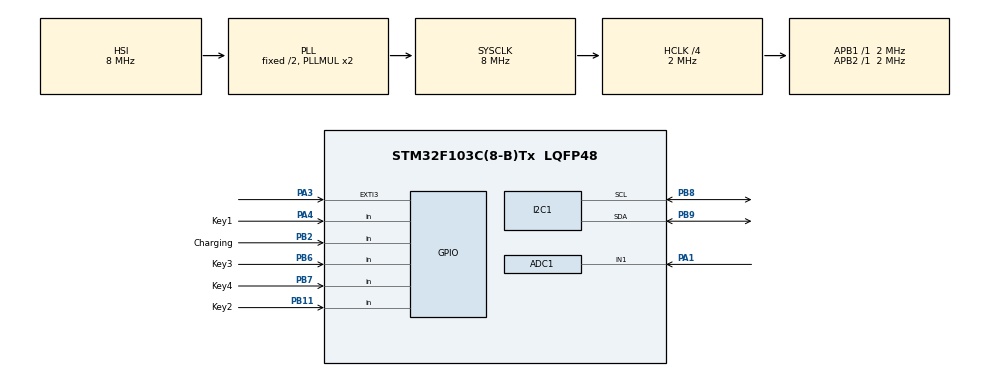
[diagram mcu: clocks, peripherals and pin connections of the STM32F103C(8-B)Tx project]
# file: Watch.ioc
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ADC1.Channel-1\#ChannelRegularConversion=ADC_CHANNEL_1
ADC1.ContinuousConvMode=ENABLE
ADC1.NbrOfConversionFlag=1
ADC1.Rank-1\#ChannelRegularConversion=1
ADC1.SamplingTime-1\#ChannelRegularConversion=ADC_SAMPLETIME_1CYCLE_5
ADC1.master=1
Mcu.Family=STM32F1
Mcu.Name=STM32F103C(8-B)Tx
Mcu.Package=LQFP48
NVIC.PriorityGroup=NVIC_PRIORITYGROUP_4
NVIC.TIM4_IRQn=true\:0\:0\:false\:false\:true\:true\:true\:true
PA1.Signal=ADCx_IN1
PA13.Mode=Serial_Wire
PA13.Signal=SYS_JTMS-SWDIO
PA14.Mode=Serial_Wire
PA14.Signal=SYS_JTCK-SWCLK
PA3.GPIO_ModeDefaultEXTI=GPIO_MODE_EVT_FALLING
PA3.GPIO_PuPd=GPIO_PULLUP
PA3.Signal=GPXTI3
PA4.GPIO_Label=Key1
PA4.GPIO_PuPd=GPIO_PULLUP
PA4.Signal=GPIO_Input
PB11.GPIO_Label=Key2
PB11.GPIO_PuPd=GPIO_PULLUP
PB11.Signal=GPIO_Input
PB2.GPIO_Label=Charging
PB2.GPIO_PuPd=GPIO_PULLDOWN
PB2.Signal=GPIO_Input
PB6.GPIO_Label=Key3
PB6.GPIO_PuPd=GPIO_PULLUP
PB6.Signal=GPIO_Input
PB7.GPIO_Label=Key4
PB7.GPIO_PuPd=GPIO_PULLUP
PB7.Signal=GPIO_Input
PB8.Mode=I2C
PB8.Signal=I2C1_SCL
PB9.Mode=I2C
PB9.Signal=I2C1_SDA
PC14-OSC32_IN.Mode=LSE-External-Oscillator
PC14-OSC32_IN.Signal=RCC_OSC32_IN
PC15-OSC32_OUT.Mode=LSE-External-Oscillator
PC15-OSC32_OUT.Signal=RCC_OSC32_OUT
ProjectManager.HeapSize=0x200
ProjectManager.StackSize=0x400
ProjectManager.TargetToolchain=CMake
RCC.AHBCLKDivider=RCC_SYSCLK_DIV4
RCC.AHBFreq_Value=2000000
RCC.APB1Freq_Value=2000000
RCC.APB1TimFreq_Value=2000000
RCC.APB2Freq_Value=2000000
RCC.APB2TimFreq_Value=2000000
RCC.HCLKFreq_Value=2000000
RCC.PLLSourceVirtual=RCC_PLLSOURCE_HSI_DIV2
RCC.RTCClockSelection=RCC_RTCCLKSOURCE_LSE
RCC.SYSCLKFreq_VALUE=8000000
RCC.SYSCLKSource=RCC_SYSCLKSOURCE_PLLCLK
RCC.USBFreq_Value=8000000
RTC.AsynchPrediv=RTC_AUTO_1_SECOND
RTC.AutoPrediv=RTC_AUTO_1_SECOND
RTC.Format=RTC_FORMAT_BIN
SH.ADCx_IN1.0=ADC1_IN1,IN1
TIM4.Period=10
TIM4.Prescaler=2000
VP_RTC_VS_RTC_Activate.Mode=RTC_Enabled
VP_TIM4_VS_ClockSourceINT.Mode=Internal
board=custom

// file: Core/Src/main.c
/* USER CODE BEGIN Header */
/**
 ******************************************************************************
 * @file           : main.c
 * @brief          : Main program body
 ******************************************************************************
 * @attention
 *
 * Copyright (c) 2025 STMicroelectronics.
 * All rights reserved.
 *
 * This software is licensed under terms that can be found in the LICENSE file
 * in the root directory of this software component.
 * If no LICENSE file comes with this software, it is provided AS-IS.
 *
 ******************************************************************************
 */
/* USER CODE END Header */
#include "main.h"
#include "adc.h"
#include "i2c.h"
#include "rtc.h"
#include "tim.h"
#include "gpio.h"

/* USER CODE BEGIN Includes */

#include "key.h"
#include "oled.h"
#include "watch.h"

/* USER CODE END Includes */

void SystemClock_Config(void);

int main(void)
{

  /* MCU Configuration--------------------------------------------------------*/

  /* Reset of all peripherals, Initializes the Flash interface and the Systick. */
  HAL_Init();

  /* Configure the system clock */
  SystemClock_Config();

  /* Initialize all configured peripherals */
  MX_GPIO_Init();
  MX_ADC1_Init();
  MX_RTC_Init();
  MX_TIM4_Init();
  MX_I2C1_Init();
  /* USER CODE BEGIN 2 */

    HAL_TIM_Base_Start_IT(&htim4);

    HAL_ADCEx_Calibration_Start(&hadc1);
    HAL_ADC_Start(&hadc1);

    oled_init();
    watch_init();

  /* USER CODE END 2 */

  /* Infinite loop */
  /* USER CODE BEGIN WHILE */
    while (1)
    {
        key_update();
        watch_update();
        oled_flush();
    /* USER CODE END WHILE */

    }
}

void SystemClock_Config(void)
{
  RCC_OscInitTypeDef RCC_OscInitStruct = {0};
  RCC_ClkInitTypeDef RCC_ClkInitStruct = {0};
  RCC_PeriphCLKInitTypeDef PeriphClkInit = {0};

  /** Initializes the RCC Oscillators according to the specified parameters
  * in the RCC_OscInitTypeDef structure.
  */
  RCC_OscInitStruct.OscillatorType = RCC_OSCILLATORTYPE_HSI|RCC_OSCILLATORTYPE_LSE;
  RCC_OscInitStruct.LSEState = RCC_LSE_ON;
  RCC_OscInitStruct.HSIState = RCC_HSI_ON;
  RCC_OscInitStruct.HSICalibrationValue = RCC_HSICALIBRATION_DEFAULT;
  RCC_OscInitStruct.PLL.PLLState = RCC_PLL_ON;
  RCC_OscInitStruct.PLL.PLLSource = RCC_PLLSOURCE_HSI_DIV2;
  RCC_OscInitStruct.PLL.PLLMUL = RCC_PLL_MUL2;
  if (HAL_RCC_OscConfig(&RCC_OscInitStruct) != HAL_OK)
  {
    Error_Handler();
  }

  /** Initializes the CPU, AHB and APB buses clocks
  */
  RCC_ClkInitStruct.ClockType = RCC_CLOCKTYPE_HCLK|RCC_CLOCKTYPE_SYSCLK
                              |RCC_CLOCKTYPE_PCLK1|RCC_CLOCKTYPE_PCLK2;
  RCC_ClkInitStruct.SYSCLKSource = RCC_SYSCLKSOURCE_PLLCLK;
  RCC_ClkInitStruct.AHBCLKDivider = RCC_SYSCLK_DIV4;
  RCC_ClkInitStruct.APB1CLKDivider = RCC_HCLK_DIV1;
  RCC_ClkInitStruct.APB2CLKDivider = RCC_HCLK_DIV1;

  if (HAL_RCC_ClockConfig(&RCC_ClkInitStruct, FLASH_LATENCY_0) != HAL_OK)
  {
    Error_Handler();
  }
  PeriphClkInit.PeriphClockSelection = RCC_PERIPHCLK_RTC|RCC_PERIPHCLK_ADC;
  PeriphClkInit.RTCClockSelection = RCC_RTCCLKSOURCE_LSE;
  PeriphClkInit.AdcClockSelection = RCC_ADCPCLK2_DIV2;
  if (HAL_RCCEx_PeriphCLKConfig(&PeriphClkInit) != HAL_OK)
  {
    Error_Handler();
  }
}

void Error_Handler(void)
{
  /* USER CODE BEGIN Error_Handler_Debug */
    /* User can add his own implementation to report the HAL error return state
     */
    __disable_irq();
    while (1)
    {
    }
  /* USER CODE END Error_Handler_Debug */
}
#ifdef USE_FULL_ASSERT
/**
  * @brief  Reports the name of the source file and the source line number
  *         where the assert_param error has occurred.
  * @param  file: pointer to the source file name
  * @param  line: assert_param error line source number
  * @retval None
  */
void assert_failed(uint8_t *file, uint32_t line)
{
  /* USER CODE BEGIN 6 */
    /* User can add his own implementation to report the file name and line
       number, ex: printf("Wrong parameters value: file %s on line %d\r\n",
       file, line) */
  /* USER CODE END 6 */
}
#endif /* USE_FULL_ASSERT */
